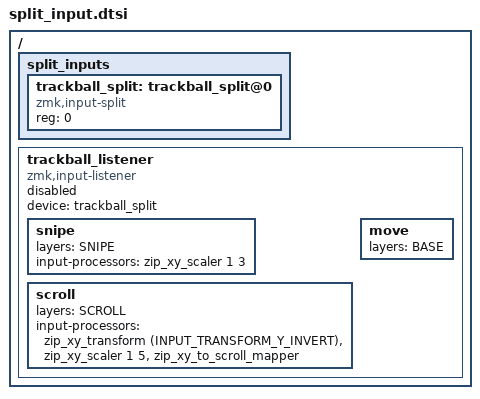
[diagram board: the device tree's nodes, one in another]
#include <dt-bindings/zmk/input_transform.h>
#include <input/processors.dtsi>

#define BASE 0
#define NUMS 1
#define DANGER 2
#define SCROLL 3
#define SNIPE 4
#define AUTO 5

/ {
  split_inputs {
    #address-cells = <1>;
    #size-cells = <0>;

    trackball_split: trackball_split@0 {
      compatible = "zmk,input-split";
      reg = <0>;
    };
  };

  trackball_listener: trackball_listener {
    compatible = "zmk,input-listener";
    status = "disabled";
    device = <&trackball_split>;

    snipe {
      layers = <SNIPE>;
      input-processors = <&zip_xy_scaler 1 3>;
    };

    scroll {
      layers = <SCROLL>;
      input-processors = <&zip_xy_transform (INPUT_TRANSFORM_Y_INVERT)>, <&zip_xy_scaler 1 5>, <&zip_xy_to_scroll_mapper>;
    };

    move {
      layers = <BASE>;
    };
  };
};


